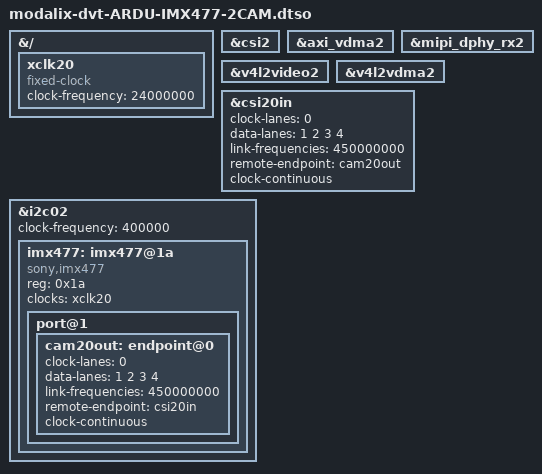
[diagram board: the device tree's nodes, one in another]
// SPDX-License-Identifier: (GPL-2.0+ OR MIT)
/*
 * Copyright (c) 2026 SiMa ai
 */

/dts-v1/;
/plugin/;

&{/} {
        xclk20: xclk20 {
                status = "okay";
                compatible = "fixed-clock";
                #clock-cells = <0>;
                clock-frequency = <24000000>;
        };
};

&csi2 {
    status = "okay";
};

&axi_vdma2 {
    status = "okay";
};

&mipi_dphy_rx2 {
    status = "okay";
};

&v4l2video2 {
    status = "okay";
};

&v4l2vdma2 {
    status = "okay";
};

&csi20in{
    clock-lanes = <0>;
    data-lanes = <1 2 3 4>;
    link-frequencies = /bits/ 64 <450000000>;
    remote-endpoint = <&cam20out>;
    clock-continuous;
};

&i2c02 {
        status = "okay";
        clock-frequency = <400000>;
        #address-cells = <1>;
        #size-cells = <0>;

        imx477: imx477@1a {
                compatible = "sony,imx477";
                reg = <0x1a>;

                clocks = <&xclk20>;
                clock-names = "xclk";

                port@1 {
                        cam20out: endpoint@0 {
                                clock-lanes = <0>;
                                data-lanes = <1 2 3 4>;
                                link-frequencies = /bits/ 64 <450000000>;
                                remote-endpoint = <&csi20in>;
                                clock-continuous;
                        };
                };
        };
};
